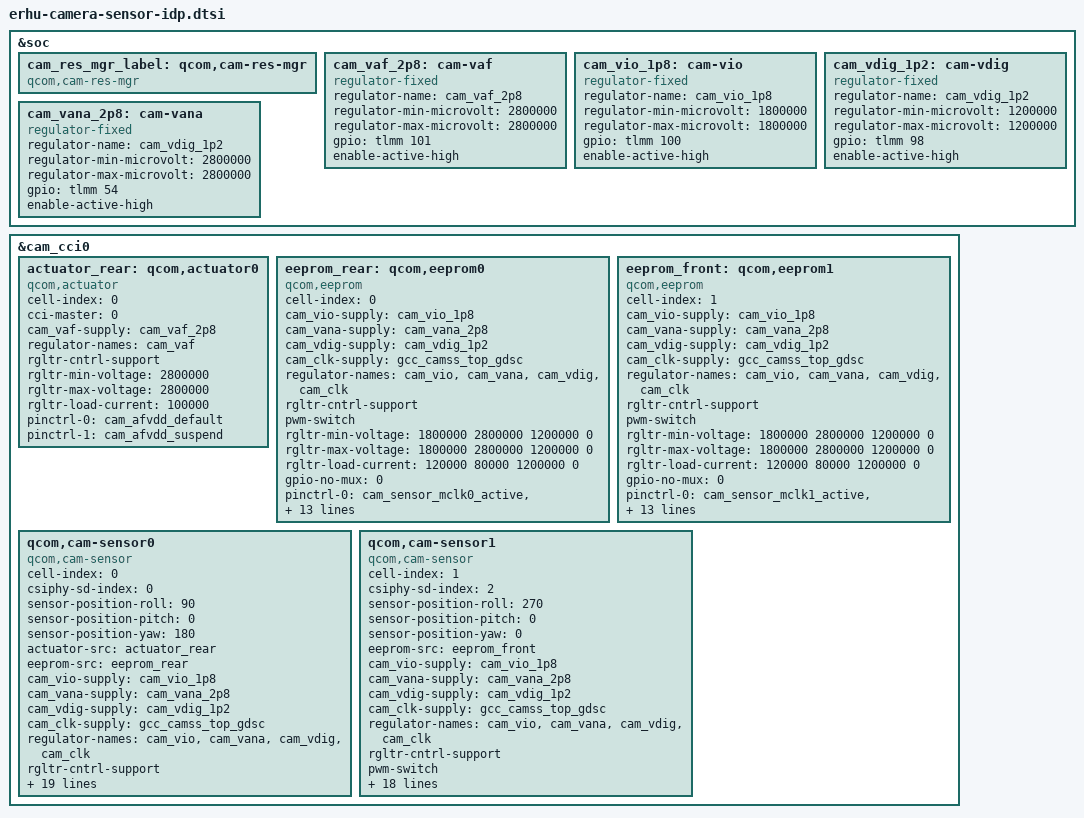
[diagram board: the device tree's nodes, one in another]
#include <dt-bindings/clock/qcom,gcc-khaje.h>
#include <dt-bindings/msm-camera.h>

&soc {
	cam_res_mgr_label: qcom,cam-res-mgr {
		compatible = "qcom,cam-res-mgr";
		status = "ok";
	};

	cam_vaf_2p8: cam-vaf {
		compatible = "regulator-fixed";
		regulator-name = "cam_vaf_2p8";
		regulator-min-microvolt = <2800000>;
		regulator-max-microvolt = <2800000>;
		gpio = <&tlmm 101 0>;
		enable-active-high;
		status = "okay";
	};

	cam_vio_1p8: cam-vio {
		compatible = "regulator-fixed";
		regulator-name = "cam_vio_1p8";
		regulator-min-microvolt = <1800000>;
		regulator-max-microvolt = <1800000>;
		gpio = <&tlmm 100 0>;
		enable-active-high;
		status = "okay";
	};

	cam_vdig_1p2: cam-vdig {
		compatible = "regulator-fixed";
		regulator-name = "cam_vdig_1p2";
		regulator-min-microvolt = <1200000>;
		regulator-max-microvolt = <1200000>;
		gpio = <&tlmm 98 0>;
		enable-active-high;
		status = "okay";
	};

	cam_vana_2p8: cam-vana {
		compatible = "regulator-fixed";
		regulator-name = "cam_vdig_1p2";
		regulator-min-microvolt = <2800000>;
		regulator-max-microvolt = <2800000>;
		gpio = <&tlmm 54 0>;
		enable-active-high;
		status = "okay";
	};
};

&cam_cci0 {
	actuator_rear: qcom,actuator0 {
		cell-index = <0>;
		compatible = "qcom,actuator";
		cci-master = <0>;
		cam_vaf-supply = <&cam_vaf_2p8>;
		regulator-names = "cam_vaf";
		rgltr-cntrl-support;
		rgltr-min-voltage = <2800000>;
		rgltr-max-voltage = <2800000>;
		rgltr-load-current = <100000>;
        pinctrl-names = "cam_default", "cam_suspend";
		pinctrl-0 = <&cam_afvdd_default>;
		pinctrl-1 = <&cam_afvdd_suspend>;
		status = "ok";
	};

	eeprom_rear: qcom,eeprom0 {
		cell-index = <0>;
		compatible = "qcom,eeprom";
		cam_vio-supply = <&cam_vio_1p8>;
		cam_vana-supply = <&cam_vana_2p8>;
		cam_vdig-supply = <&cam_vdig_1p2>;
		cam_clk-supply = <&gcc_camss_top_gdsc>;
		regulator-names = "cam_vio", "cam_vana", "cam_vdig",
			"cam_clk";
		rgltr-cntrl-support;
		pwm-switch;
		rgltr-min-voltage = <1800000 2800000 1200000 0>;
		rgltr-max-voltage = <1800000 2800000 1200000 0>;
		rgltr-load-current = <120000 80000 1200000 0>;
		gpio-no-mux = <0>;
		pinctrl-names = "cam_default", "cam_suspend";
		pinctrl-0 = <&cam_sensor_mclk0_active
				&cam_sensor_rear0_reset_active>;
		pinctrl-1 = <&cam_sensor_mclk0_suspend
				&cam_sensor_rear0_reset_suspend>;
		gpios = <&tlmm 20 0>,
			<&tlmm 19 0>;
		gpio-reset = <1>;
		gpio-req-tbl-num = <0 1>;
		gpio-req-tbl-flags = <1 0>;
		gpio-req-tbl-label = "CAMIF_MCLK0",
					"CAM_RESET0";
		sensor-mode = <0>;
		cci-master = <0>;
		status = "ok";
		clocks = <&gcc GCC_CAMSS_MCLK0_CLK>;
		clock-names = "cam_clk";
		clock-cntl-level = "turbo";
		clock-rates = <19200000>;
	};

	eeprom_front: qcom,eeprom1 {
		cell-index = <1>;
		compatible = "qcom,eeprom";
		cam_vio-supply = <&cam_vio_1p8>;
		cam_vana-supply = <&cam_vana_2p8>;
		cam_vdig-supply = <&cam_vdig_1p2>;
		cam_clk-supply = <&gcc_camss_top_gdsc>;
		regulator-names = "cam_vio", "cam_vana", "cam_vdig",
			"cam_clk";
		rgltr-cntrl-support;
		pwm-switch;
		rgltr-min-voltage = <1800000 2800000 1200000 0>;
		rgltr-max-voltage = <1800000 2800000 1200000 0>;
		rgltr-load-current = <120000 80000 1200000 0>;
		gpio-no-mux = <0>;
		pinctrl-names = "cam_default", "cam_suspend";
		pinctrl-0 = <&cam_sensor_mclk1_active
				&cam_sensor_front0_reset_active>;
		pinctrl-1 = <&cam_sensor_mclk1_suspend
				&cam_sensor_front0_reset_suspend>;
		gpios = <&tlmm 21 0>,
			<&tlmm 24 0>;
		gpio-reset = <1>;
		gpio-req-tbl-num = <0 1>;
		gpio-req-tbl-flags = <1 0>;
		gpio-req-tbl-label = "CAMIF_MCLK1",
					"CAM_RESET1";
		sensor-mode = <0>;
		cci-master = <1>;
		status = "ok";
		clocks = <&gcc GCC_CAMSS_MCLK1_CLK>;
		clock-names = "cam_clk";
		clock-cntl-level = "turbo";
		clock-rates = <19200000>;
	};

	 /* Rear*/
	qcom,cam-sensor0 {
		cell-index = <0>;
		compatible = "qcom,cam-sensor";
		csiphy-sd-index = <0>;
		sensor-position-roll = <90>;
		sensor-position-pitch = <0>;
		sensor-position-yaw = <180>;
		actuator-src = <&actuator_rear>;
		//led-flash-src = <&led_flash_rear>;
		eeprom-src = <&eeprom_rear>;
		cam_vio-supply = <&cam_vio_1p8>;
		cam_vana-supply = <&cam_vana_2p8>;
		cam_vdig-supply = <&cam_vdig_1p2>;
		cam_clk-supply = <&gcc_camss_top_gdsc>;
		regulator-names = "cam_vio", "cam_vana", "cam_vdig",
			"cam_clk";
		rgltr-cntrl-support;
		pwm-switch;
		rgltr-min-voltage = <1800000 2800000 1200000 0>;
		rgltr-max-voltage = <1800000 2800000 1200000 0>;
		rgltr-load-current = <120000 80000 1200000 0>;
		gpio-no-mux = <0>;
		pinctrl-names = "cam_default", "cam_suspend";
		pinctrl-0 = <&cam_sensor_mclk0_active
				&cam_sensor_rear0_reset_active>;
		pinctrl-1 = <&cam_sensor_mclk0_suspend
				&cam_sensor_rear0_reset_suspend>;
		gpios = <&tlmm 20 0>,
			<&tlmm 19 0>;
		gpio-reset = <1>;
		gpio-req-tbl-num = <0 1>;
		gpio-req-tbl-flags = <1 0>;
		gpio-req-tbl-label = "CAMIF_MCLK0",
					"CAM_RESET0";
		sensor-mode = <0>;
		cci-master = <0>;
		status = "ok";
		clocks = <&gcc GCC_CAMSS_MCLK0_CLK>;
		clock-names = "cam_clk";
		clock-cntl-level = "turbo";
		clock-rates = <19200000>;
	};

	/*Front*/
	qcom,cam-sensor1 {
		cell-index = <1>;
		compatible = "qcom,cam-sensor";
		csiphy-sd-index = <2>;
		sensor-position-roll = <270>;
		sensor-position-pitch = <0>;
		sensor-position-yaw = <0>;
		eeprom-src = <&eeprom_front>;
		cam_vio-supply = <&cam_vio_1p8>;
		cam_vana-supply = <&cam_vana_2p8>;
		cam_vdig-supply = <&cam_vdig_1p2>;
		cam_clk-supply = <&gcc_camss_top_gdsc>;
		regulator-names = "cam_vio", "cam_vana", "cam_vdig",
			"cam_clk";
		rgltr-cntrl-support;
		pwm-switch;
		rgltr-min-voltage = <1800000 2800000 1200000 0>;
		rgltr-max-voltage = <1800000 2800000 1200000 0>;
		rgltr-load-current = <120000 80000 1200000 0>;
		gpio-no-mux = <0>;
		pinctrl-names = "cam_default", "cam_suspend";
		pinctrl-0 = <&cam_sensor_mclk1_active
				&cam_sensor_front0_reset_active>;
		pinctrl-1 = <&cam_sensor_mclk1_suspend
				&cam_sensor_front0_reset_suspend>;
		gpios = <&tlmm 21 0>,
			<&tlmm 24 0>;
		gpio-reset = <1>;
		gpio-req-tbl-num = <0 1>;
		gpio-req-tbl-flags = <1 0>;
		gpio-req-tbl-label = "CAMIF_MCLK1",
					"CAM_RESET1";
		sensor-mode = <0>;
		cci-master = <1>;
		status = "ok";
		clocks = <&gcc GCC_CAMSS_MCLK1_CLK>;
		clock-names = "cam_clk";
		clock-cntl-level = "turbo";
		clock-rates = <19200000>;		
	};
};
